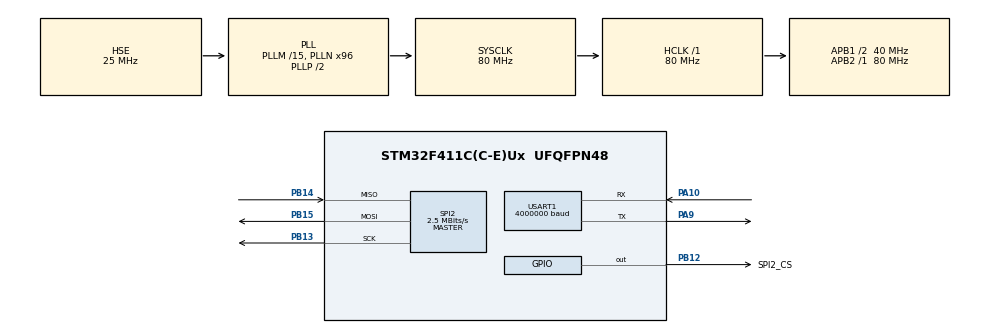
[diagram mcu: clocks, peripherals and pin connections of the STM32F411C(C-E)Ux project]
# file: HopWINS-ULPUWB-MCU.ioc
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Dma.Request0=USART1_TX
Dma.Request1=SPI2_RX
Dma.Request2=SPI2_TX
Dma.SPI2_RX.1.Direction=DMA_PERIPH_TO_MEMORY
Dma.SPI2_RX.1.FIFOMode=DMA_FIFOMODE_DISABLE
Dma.SPI2_RX.1.Instance=DMA1_Stream3
Dma.SPI2_RX.1.MemDataAlignment=DMA_MDATAALIGN_BYTE
Dma.SPI2_RX.1.MemInc=DMA_MINC_ENABLE
Dma.SPI2_RX.1.Mode=DMA_NORMAL
Dma.SPI2_RX.1.PeriphDataAlignment=DMA_PDATAALIGN_BYTE
Dma.SPI2_RX.1.PeriphInc=DMA_PINC_DISABLE
Dma.SPI2_RX.1.Priority=DMA_PRIORITY_VERY_HIGH
Dma.SPI2_TX.2.Direction=DMA_MEMORY_TO_PERIPH
Dma.SPI2_TX.2.FIFOMode=DMA_FIFOMODE_DISABLE
Dma.SPI2_TX.2.Instance=DMA1_Stream4
Dma.SPI2_TX.2.MemDataAlignment=DMA_MDATAALIGN_BYTE
Dma.SPI2_TX.2.MemInc=DMA_MINC_ENABLE
Dma.SPI2_TX.2.Mode=DMA_NORMAL
Dma.SPI2_TX.2.PeriphDataAlignment=DMA_PDATAALIGN_BYTE
Dma.SPI2_TX.2.PeriphInc=DMA_PINC_DISABLE
Dma.SPI2_TX.2.Priority=DMA_PRIORITY_HIGH
Dma.USART1_TX.0.Direction=DMA_MEMORY_TO_PERIPH
Dma.USART1_TX.0.FIFOMode=DMA_FIFOMODE_DISABLE
Dma.USART1_TX.0.Instance=DMA2_Stream7
Dma.USART1_TX.0.MemDataAlignment=DMA_MDATAALIGN_BYTE
Dma.USART1_TX.0.MemInc=DMA_MINC_ENABLE
Dma.USART1_TX.0.Mode=DMA_NORMAL
Dma.USART1_TX.0.PeriphDataAlignment=DMA_PDATAALIGN_BYTE
Dma.USART1_TX.0.PeriphInc=DMA_PINC_DISABLE
Dma.USART1_TX.0.Priority=DMA_PRIORITY_MEDIUM
Mcu.Family=STM32F4
Mcu.Name=STM32F411C(C-E)Ux
Mcu.Package=UFQFPN48
NVIC.DMA1_Stream3_IRQn=true\:1\:0\:false\:false\:true\:false\:true\:true
NVIC.DMA1_Stream4_IRQn=true\:1\:0\:false\:false\:true\:false\:true\:true
NVIC.DMA2_Stream7_IRQn=true\:3\:0\:false\:false\:true\:false\:true\:true
NVIC.PriorityGroup=NVIC_PRIORITYGROUP_4
NVIC.USART1_IRQn=true\:3\:0\:false\:false\:true\:true\:true\:true
PA10.Mode=Asynchronous
PA10.Signal=USART1_RX
PA13.Mode=Trace_Asynchronous_SW
PA13.Signal=SYS_JTMS-SWDIO
PA14.Mode=Trace_Asynchronous_SW
PA14.Signal=SYS_JTCK-SWCLK
PA9.Mode=Asynchronous
PA9.Signal=USART1_TX
PB12.GPIO_Label=SPI2_CS
PB12.GPIO_Speed=GPIO_SPEED_FREQ_VERY_HIGH
PB12.PinState=GPIO_PIN_SET
PB12.Signal=GPIO_Output
PB13.Mode=Full_Duplex_Master
PB13.Signal=SPI2_SCK
PB14.Mode=Full_Duplex_Master
PB14.Signal=SPI2_MISO
PB15.Mode=Full_Duplex_Master
PB15.Signal=SPI2_MOSI
PB3.Mode=Trace_Asynchronous_SW
PB3.Signal=SYS_JTDO-SWO
PH0\ -\ OSC_IN.Mode=HSE-External-Oscillator
PH0\ -\ OSC_IN.Signal=RCC_OSC_IN
PH1\ -\ OSC_OUT.Mode=HSE-External-Oscillator
PH1\ -\ OSC_OUT.Signal=RCC_OSC_OUT
ProjectManager.HeapSize=0x200
ProjectManager.StackSize=0x400
ProjectManager.TargetToolchain=CMake
RCC.48MHZClocksFreq_Value=40000000
RCC.AHBFreq_Value=80000000
RCC.APB1CLKDivider=RCC_HCLK_DIV2
RCC.APB1Freq_Value=40000000
RCC.APB1TimFreq_Value=80000000
RCC.APB2Freq_Value=80000000
RCC.APB2TimFreq_Value=80000000
RCC.CortexFreq_Value=80000000
RCC.HCLKFreq_Value=80000000
RCC.HSE_VALUE=25000000
RCC.HSI_VALUE=16000000
RCC.LSE_VALUE=32768
RCC.PLLM=15
RCC.PLLN=96
RCC.PLLSourceVirtual=RCC_PLLSOURCE_HSE
RCC.PWR_Regulator_Voltage_Scale=PWR_REGULATOR_VOLTAGE_SCALE2
RCC.SYSCLKFreq_VALUE=80000000
RCC.SYSCLKSource=RCC_SYSCLKSOURCE_PLLCLK
RCC.VCOOutputFreq_Value=160000000
SPI2.BaudRatePrescaler=SPI_BAUDRATEPRESCALER_16
SPI2.CRCCalculation=SPI_CRCCALCULATION_DISABLE
SPI2.CalculateBaudRate=2.5 MBits/s
SPI2.Direction=SPI_DIRECTION_2LINES
SPI2.Mode=SPI_MODE_MASTER
SPI2.VirtualType=VM_MASTER
USART1.BaudRate=4000000
USART1.Mode=MODE_TX
USART1.OverSampling=UART_OVERSAMPLING_8
USART1.VirtualMode=VM_ASYNC
VP_CRC_VS_CRC.Mode=CRC_Activate
board=custom

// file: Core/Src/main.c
/* USER CODE BEGIN Header */
/**
  ******************************************************************************
  * @file           : main.c
  * @brief          : Main program body
  ******************************************************************************
  * @attention
  *
  * Copyright (c) 2026 STMicroelectronics.
  * All rights reserved.
  *
  * This software is licensed under terms that can be found in the LICENSE file
  * in the root directory of this software component.
  * If no LICENSE file comes with this software, it is provided AS-IS.
  *
  ******************************************************************************
  */
/* USER CODE END Header */
#include "main.h"

/* USER CODE BEGIN Includes */
#include "hopwins_serial.h"
#include "hopwins_uwb_service.h"

/* USER CODE END Includes */

CRC_HandleTypeDef hcrc;

SPI_HandleTypeDef hspi2;
DMA_HandleTypeDef hdma_spi2_rx;
DMA_HandleTypeDef hdma_spi2_tx;

UART_HandleTypeDef huart1;
DMA_HandleTypeDef hdma_usart1_tx;

void SystemClock_Config(void);
static void MX_GPIO_Init(void);
static void MX_DMA_Init(void);
static void MX_USART1_UART_Init(void);
static void MX_CRC_Init(void);
static void MX_SPI2_Init(void);

int main(void)
{

  /* MCU Configuration--------------------------------------------------------*/

  /* Reset of all peripherals, Initializes the Flash interface and the Systick. */
  HAL_Init();

  /* Configure the system clock */
  SystemClock_Config();

  /* USER CODE BEGIN SysInit */
  /* The PLL runs from HSE; disable the reset-default HSI to save power. */
  __HAL_RCC_HSI_DISABLE();
  /* USER CODE END SysInit */

  /* Initialize all configured peripherals */
  MX_GPIO_Init();
  MX_DMA_Init();
  MX_USART1_UART_Init();
  MX_CRC_Init();
  MX_SPI2_Init();
  /* USER CODE BEGIN 2 */
  if (hopwins_serial_init() != HOPWINS_SERIAL_STATUS_OK)
  {
    Error_Handler();
  }
  (void)hopwins_serial_send((const uint8_t *)"[MCU] boot; peripherals ready\r\n",
                            sizeof("[MCU] boot; peripherals ready\r\n") - 1U);

  if (!hopwins_uwb_init() || !hopwins_uwb_periodic_tx_start())
  {
    (void)hopwins_serial_send((const uint8_t *)"[MCU] UWB service failed\r\n",
                              sizeof("[MCU] UWB service failed\r\n") - 1U);
    Error_Handler();
  }

  /* USER CODE END 2 */

  /* Infinite loop */
  while (1)
  {

    /* USER CODE BEGIN 3 */
    hopwins_uwb_periodic_tx_process();
  }
  /* USER CODE END 3 */
}

void SystemClock_Config(void)
{
  RCC_OscInitTypeDef RCC_OscInitStruct = {0};
  RCC_ClkInitTypeDef RCC_ClkInitStruct = {0};

  /** Configure the main internal regulator output voltage
  */
  __HAL_RCC_PWR_CLK_ENABLE();
  __HAL_PWR_VOLTAGESCALING_CONFIG(PWR_REGULATOR_VOLTAGE_SCALE2);

  /** Initializes the RCC Oscillators according to the specified parameters
  * in the RCC_OscInitTypeDef structure.
  */
  RCC_OscInitStruct.OscillatorType = RCC_OSCILLATORTYPE_HSE;
  RCC_OscInitStruct.HSEState = RCC_HSE_ON;
  RCC_OscInitStruct.PLL.PLLState = RCC_PLL_ON;
  RCC_OscInitStruct.PLL.PLLSource = RCC_PLLSOURCE_HSE;
  RCC_OscInitStruct.PLL.PLLM = 15;
  RCC_OscInitStruct.PLL.PLLN = 96;
  RCC_OscInitStruct.PLL.PLLP = RCC_PLLP_DIV2;
  RCC_OscInitStruct.PLL.PLLQ = 4;
  if (HAL_RCC_OscConfig(&RCC_OscInitStruct) != HAL_OK)
  {
    Error_Handler();
  }

  /** Initializes the CPU, AHB and APB buses clocks
  */
  RCC_ClkInitStruct.ClockType = RCC_CLOCKTYPE_HCLK|RCC_CLOCKTYPE_SYSCLK
                              |RCC_CLOCKTYPE_PCLK1|RCC_CLOCKTYPE_PCLK2;
  RCC_ClkInitStruct.SYSCLKSource = RCC_SYSCLKSOURCE_PLLCLK;
  RCC_ClkInitStruct.AHBCLKDivider = RCC_SYSCLK_DIV1;
  RCC_ClkInitStruct.APB1CLKDivider = RCC_HCLK_DIV2;
  RCC_ClkInitStruct.APB2CLKDivider = RCC_HCLK_DIV1;

  if (HAL_RCC_ClockConfig(&RCC_ClkInitStruct, FLASH_LATENCY_2) != HAL_OK)
  {
    Error_Handler();
  }
}

static void MX_CRC_Init(void)
{

  hcrc.Instance = CRC;
  if (HAL_CRC_Init(&hcrc) != HAL_OK)
  {
    Error_Handler();
  }

}

static void MX_SPI2_Init(void)
{

  /* SPI2 parameter configuration*/
  hspi2.Instance = SPI2;
  hspi2.Init.Mode = SPI_MODE_MASTER;
  hspi2.Init.Direction = SPI_DIRECTION_2LINES;
  hspi2.Init.DataSize = SPI_DATASIZE_8BIT;
  hspi2.Init.CLKPolarity = SPI_POLARITY_LOW;
  hspi2.Init.CLKPhase = SPI_PHASE_1EDGE;
  hspi2.Init.NSS = SPI_NSS_SOFT;
  hspi2.Init.BaudRatePrescaler = SPI_BAUDRATEPRESCALER_16;
  hspi2.Init.FirstBit = SPI_FIRSTBIT_MSB;
  hspi2.Init.TIMode = SPI_TIMODE_DISABLE;
  hspi2.Init.CRCCalculation = SPI_CRCCALCULATION_DISABLE;
  hspi2.Init.CRCPolynomial = 10;
  if (HAL_SPI_Init(&hspi2) != HAL_OK)
  {
    Error_Handler();
  }

}

static void MX_USART1_UART_Init(void)
{

  huart1.Instance = USART1;
  huart1.Init.BaudRate = 4000000;
  huart1.Init.WordLength = UART_WORDLENGTH_8B;
  huart1.Init.StopBits = UART_STOPBITS_1;
  huart1.Init.Parity = UART_PARITY_NONE;
  huart1.Init.Mode = UART_MODE_TX;
  huart1.Init.HwFlowCtl = UART_HWCONTROL_NONE;
  huart1.Init.OverSampling = UART_OVERSAMPLING_8;
  if (HAL_UART_Init(&huart1) != HAL_OK)
  {
    Error_Handler();
  }

}

static void MX_DMA_Init(void)
{

  /* DMA controller clock enable */
  __HAL_RCC_DMA2_CLK_ENABLE();
  __HAL_RCC_DMA1_CLK_ENABLE();

  /* DMA interrupt init */
  /* DMA1_Stream3_IRQn interrupt configuration */
  HAL_NVIC_SetPriority(DMA1_Stream3_IRQn, 1, 0);
  HAL_NVIC_EnableIRQ(DMA1_Stream3_IRQn);
  /* DMA1_Stream4_IRQn interrupt configuration */
  HAL_NVIC_SetPriority(DMA1_Stream4_IRQn, 1, 0);
  HAL_NVIC_EnableIRQ(DMA1_Stream4_IRQn);
  /* DMA2_Stream7_IRQn interrupt configuration */
  HAL_NVIC_SetPriority(DMA2_Stream7_IRQn, 3, 0);
  HAL_NVIC_EnableIRQ(DMA2_Stream7_IRQn);

}

static void MX_GPIO_Init(void)
{
  GPIO_InitTypeDef GPIO_InitStruct = {0};

  /* GPIO Ports Clock Enable */
  __HAL_RCC_GPIOC_CLK_ENABLE();
  __HAL_RCC_GPIOH_CLK_ENABLE();
  __HAL_RCC_GPIOA_CLK_ENABLE();
  __HAL_RCC_GPIOB_CLK_ENABLE();

  /*Configure GPIO pin Output Level */
  HAL_GPIO_WritePin(SPI2_CS_GPIO_Port, SPI2_CS_Pin, GPIO_PIN_SET);

  /*Configure GPIO pins : PC13 PC14 PC15 */
  GPIO_InitStruct.Pin = GPIO_PIN_13|GPIO_PIN_14|GPIO_PIN_15;
  GPIO_InitStruct.Mode = GPIO_MODE_ANALOG;
  GPIO_InitStruct.Pull = GPIO_NOPULL;
  HAL_GPIO_Init(GPIOC, &GPIO_InitStruct);

  /*Configure GPIO pins : PA0 PA1 PA2 PA3
                           PA4 PA5 PA6 PA7
                           PA8 PA11 PA12 PA15 */
  GPIO_InitStruct.Pin = GPIO_PIN_0|GPIO_PIN_1|GPIO_PIN_2|GPIO_PIN_3
                          |GPIO_PIN_4|GPIO_PIN_5|GPIO_PIN_6|GPIO_PIN_7
                          |GPIO_PIN_8|GPIO_PIN_11|GPIO_PIN_12|GPIO_PIN_15;
  GPIO_InitStruct.Mode = GPIO_MODE_ANALOG;
  GPIO_InitStruct.Pull = GPIO_NOPULL;
  HAL_GPIO_Init(GPIOA, &GPIO_InitStruct);

  /*Configure GPIO pins : PB0 PB1 PB2 PB10
                           PB4 PB5 PB6 PB7
                           PB8 PB9 */
  GPIO_InitStruct.Pin = GPIO_PIN_0|GPIO_PIN_1|GPIO_PIN_2|GPIO_PIN_10
                          |GPIO_PIN_4|GPIO_PIN_5|GPIO_PIN_6|GPIO_PIN_7
                          |GPIO_PIN_8|GPIO_PIN_9;
  GPIO_InitStruct.Mode = GPIO_MODE_ANALOG;
  GPIO_InitStruct.Pull = GPIO_NOPULL;
  HAL_GPIO_Init(GPIOB, &GPIO_InitStruct);

  /*Configure GPIO pin : SPI2_CS_Pin */
  GPIO_InitStruct.Pin = SPI2_CS_Pin;
  GPIO_InitStruct.Mode = GPIO_MODE_OUTPUT_PP;
  GPIO_InitStruct.Pull = GPIO_NOPULL;
  GPIO_InitStruct.Speed = GPIO_SPEED_FREQ_VERY_HIGH;
  HAL_GPIO_Init(SPI2_CS_GPIO_Port, &GPIO_InitStruct);

}

void Error_Handler(void)
{
  __disable_irq();
  while (1)
  {
  }
}
